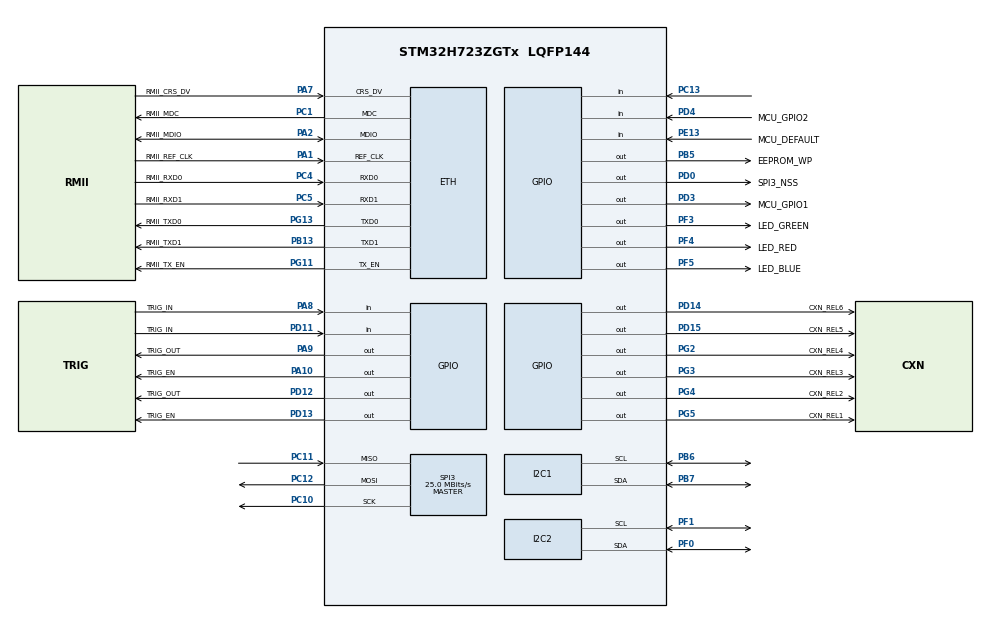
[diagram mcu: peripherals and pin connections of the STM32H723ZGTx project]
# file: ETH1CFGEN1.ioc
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CORTEX_M7.AccessPermission-Cortex_Memory_Protection_Unit_Region0_Settings=MPU_REGION_NO_ACCESS
CORTEX_M7.AccessPermission-Cortex_Memory_Protection_Unit_Region1_Settings=MPU_REGION_FULL_ACCESS
CORTEX_M7.AccessPermission-Cortex_Memory_Protection_Unit_Region2_Settings=MPU_REGION_FULL_ACCESS
CORTEX_M7.AccessPermission_S-Cortex_Memory_Protection_Unit_Region1_Settings_S=MPU_REGION_FULL_ACCESS
CORTEX_M7.AccessPermission_S-Cortex_Memory_Protection_Unit_Region2_Settings_S=MPU_REGION_FULL_ACCESS
CORTEX_M7.BaseAddress-Cortex_Memory_Protection_Unit_Region0_Settings=0x0
CORTEX_M7.BaseAddress-Cortex_Memory_Protection_Unit_Region1_Settings=0x30000000
CORTEX_M7.BaseAddress-Cortex_Memory_Protection_Unit_Region2_Settings=0x30004000
CORTEX_M7.BaseAddress_S-Cortex_Memory_Protection_Unit_Region1_Settings_S=0x30000000
CORTEX_M7.BaseAddress_S-Cortex_Memory_Protection_Unit_Region2_Settings_S=0x30000000
CORTEX_M7.CPU_DCache=Enabled
CORTEX_M7.CPU_ICache=Enabled
CORTEX_M7.DisableExec-Cortex_Memory_Protection_Unit_Region0_Settings=MPU_INSTRUCTION_ACCESS_DISABLE
CORTEX_M7.DisableExec-Cortex_Memory_Protection_Unit_Region1_Settings=MPU_INSTRUCTION_ACCESS_ENABLE
CORTEX_M7.DisableExec_S-Cortex_Memory_Protection_Unit_Region1_Settings_S=MPU_INSTRUCTION_ACCESS_DISABLE
CORTEX_M7.DisableExec_S-Cortex_Memory_Protection_Unit_Region2_Settings_S=MPU_INSTRUCTION_ACCESS_DISABLE
CORTEX_M7.Enable-Cortex_Memory_Protection_Unit_Region0_Settings=MPU_REGION_ENABLE
CORTEX_M7.Enable-Cortex_Memory_Protection_Unit_Region1_Settings=MPU_REGION_ENABLE
CORTEX_M7.Enable-Cortex_Memory_Protection_Unit_Region2_Settings=MPU_REGION_ENABLE
CORTEX_M7.Enable_S-Cortex_Memory_Protection_Unit_Region1_Settings_S=MPU_REGION_ENABLE
CORTEX_M7.Enable_S-Cortex_Memory_Protection_Unit_Region2_Settings_S=MPU_REGION_ENABLE
CORTEX_M7.IsBufferable-Cortex_Memory_Protection_Unit_Region0_Settings=MPU_ACCESS_BUFFERABLE
CORTEX_M7.IsBufferable-Cortex_Memory_Protection_Unit_Region1_Settings=MPU_ACCESS_BUFFERABLE
CORTEX_M7.IsBufferable_S-Cortex_Memory_Protection_Unit_Region2_Settings_S=MPU_ACCESS_BUFFERABLE
CORTEX_M7.IsShareable-Cortex_Memory_Protection_Unit_Region0_Settings=MPU_ACCESS_SHAREABLE
CORTEX_M7.IsShareable-Cortex_Memory_Protection_Unit_Region1_Settings=MPU_ACCESS_NOT_SHAREABLE
CORTEX_M7.IsShareable-Cortex_Memory_Protection_Unit_Region2_Settings=MPU_ACCESS_SHAREABLE
CORTEX_M7.IsShareable_S-Cortex_Memory_Protection_Unit_Region2_Settings_S=MPU_ACCESS_SHAREABLE
CORTEX_M7.MPU_Control=MPU_PRIVILEGED_DEFAULT
CORTEX_M7.Size-Cortex_Memory_Protection_Unit_Region0_Settings=MPU_REGION_SIZE_4GB
CORTEX_M7.Size-Cortex_Memory_Protection_Unit_Region1_Settings=MPU_REGION_SIZE_1KB
CORTEX_M7.Size-Cortex_Memory_Protection_Unit_Region2_Settings=MPU_REGION_SIZE_16KB
CORTEX_M7.Size_S-Cortex_Memory_Protection_Unit_Region1_Settings_S=MPU_REGION_SIZE_1KB
CORTEX_M7.Size_S-Cortex_Memory_Protection_Unit_Region2_Settings_S=MPU_REGION_SIZE_512B
CORTEX_M7.SubRegionDisable-Cortex_Memory_Protection_Unit_Region0_Settings=0x87
CORTEX_M7.TypeExtField-Cortex_Memory_Protection_Unit_Region0_Settings=MPU_TEX_LEVEL0
CORTEX_M7.TypeExtField-Cortex_Memory_Protection_Unit_Region2_Settings=MPU_TEX_LEVEL1
CORTEX_M7.TypeExtField_S-Cortex_Memory_Protection_Unit_Region1_Settings_S=MPU_TEX_LEVEL0
CORTEX_M7.default_mode_Activation=0
ETH.MediaInterface=HAL_ETH_RMII_MODE
FREERTOS.Tasks01=defaultTask,24,512,StartDefaultTask,Default,NULL,Dynamic,NULL,NULL
FREERTOS.configUSE_NEWLIB_REENTRANT=1
I2C1.Timing=0x20A0A3F6
I2C2.Timing=0x20A0A3F6
LWIP.BSP.number=1
LWIP.IP_ADDRESS=192.168.001.124
LWIP.LWIP_DHCP=0
LWIP.LWIP_RAM_HEAP_POINTER=0x30004000
LWIP.MEM_SIZE=1024*14
LWIP.NETMASK_ADDRESS=255.255.255.000
LWIP.TCP_MSS=1460
LWIP.TCP_SND_BUF=5840
LWIP.TCP_SND_QUEUELEN=16
LWIP.Version=v2.1.2_Cube
LWIP0.BSP.STBoard=false
LWIP0.BSP.api=BSP_COMPONENT_DRIVER
LWIP0.BSP.component=LAN8742
LWIP0.BSP.instance=LAN8742
LWIP0.BSP.name=Driver_PHY
LWIP0.BSP.semaphore=S_LAN8742
LWIP0.BSP.solution=LAN8742
Mcu.Family=STM32H7
Mcu.Name=STM32H723ZGTx
Mcu.Package=LQFP144
NVIC.ETH_IRQn=true\:5\:0\:false\:false\:true\:true\:true\:true\:true
NVIC.PriorityGroup=NVIC_PRIORITYGROUP_4
NVIC.TIM6_DAC_IRQn=true\:15\:0\:false\:false\:true\:false\:false\:true\:true
NVIC.TimeBase=TIM6_DAC_IRQn
NVIC.TimeBaseIP=TIM6
PA1.GPIO_Label=RMII_REF_CLK
PA1.GPIO_Speed=GPIO_SPEED_FREQ_VERY_HIGH
PA1.Mode=RMII
PA1.Signal=ETH_REF_CLK
PA10.GPIO_Label=TRIG_EN
PA10.Signal=GPIO_Output
PA13(JTMS/SWDIO).GPIO_Label=SWDIO
PA13(JTMS/SWDIO).Mode=Trace_Asynchronous_SW
PA13(JTMS/SWDIO).Signal=DEBUG_JTMS-SWDIO
PA14(JTCK/SWCLK).GPIO_Label=SWCLK
PA14(JTCK/SWCLK).Mode=Trace_Asynchronous_SW
PA14(JTCK/SWCLK).Signal=DEBUG_JTCK-SWCLK
PA2.GPIO_Label=RMII_MDIO
PA2.GPIO_Speed=GPIO_SPEED_FREQ_VERY_HIGH
PA2.Mode=RMII
PA2.Signal=ETH_MDIO
PA7.GPIO_Label=RMII_CRS_DV
PA7.GPIO_Speed=GPIO_SPEED_FREQ_VERY_HIGH
PA7.Mode=RMII
PA7.Signal=ETH_CRS_DV
PA8.GPIO_Label=TRIG_IN
PA8.Signal=GPIO_Input
PA9.GPIO_Label=TRIG_OUT
PA9.Signal=GPIO_Output
PB13.GPIO_Label=RMII_TXD1
PB13.GPIO_Speed=GPIO_SPEED_FREQ_VERY_HIGH
PB13.Mode=RMII
PB13.Signal=ETH_TXD1
PB3(JTDO/TRACESWO).GPIO_Label=SWO
PB3(JTDO/TRACESWO).Mode=Trace_Asynchronous_SW
PB3(JTDO/TRACESWO).Signal=DEBUG_JTDO-SWO
PB5.GPIO_Label=EEPROM_WP
PB5.Signal=GPIO_Output
PB6.Mode=I2C
PB6.Signal=I2C1_SCL
PB7.Mode=I2C
PB7.Signal=I2C1_SDA
PC1.GPIO_Label=RMII_MDC
PC1.Mode=RMII
PC1.Signal=ETH_MDC
PC10.Mode=Full_Duplex_Master
PC10.Signal=SPI3_SCK
PC11.Mode=Full_Duplex_Master
PC11.Signal=SPI3_MISO
PC12.Mode=Full_Duplex_Master
PC12.Signal=SPI3_MOSI
PC13.Signal=GPIO_Input
PC4.GPIO_Label=RMII_RXD0
PC4.GPIO_Speed=GPIO_SPEED_FREQ_VERY_HIGH
PC4.Mode=RMII
PC4.Signal=ETH_RXD0
PC5.GPIO_Label=RMII_RXD1
PC5.GPIO_Speed=GPIO_SPEED_FREQ_VERY_HIGH
PC5.Mode=RMII
PC5.Signal=ETH_RXD1
PD0.GPIO_Label=SPI3_NSS
PD0.GPIO_PuPd=GPIO_PULLDOWN
PD0.GPIO_Speed=GPIO_SPEED_FREQ_VERY_HIGH
PD0.PinState=GPIO_PIN_SET
PD0.Signal=GPIO_Output
PD11.GPIO_Label=TRIG_IN
PD11.Signal=GPIO_Input
PD12.GPIO_Label=TRIG_OUT
PD12.Signal=GPIO_Output
PD13.GPIO_Label=TRIG_EN
PD13.Signal=GPIO_Output
PD14.GPIO_Label=CXN_REL6
PD14.Signal=GPIO_Output
PD15.GPIO_Label=CXN_REL5
PD15.Signal=GPIO_Output
PD3.GPIO_Label=MCU_GPIO1
PD3.GPIO_Speed=GPIO_SPEED_FREQ_HIGH
PD3.PinState=GPIO_PIN_SET
PD3.Signal=GPIO_Output
PD4.GPIO_Label=MCU_GPIO2
PD4.Signal=GPIO_Input
PE13.GPIO_Label=MCU_DEFAULT
PE13.Signal=GPIO_Input
PF0.Mode=I2C
PF0.Signal=I2C2_SDA
PF1.Mode=I2C
PF1.Signal=I2C2_SCL
PF3.GPIO_Label=LED_GREEN
PF3.Signal=GPIO_Output
PF4.GPIO_Label=LED_RED
PF4.Signal=GPIO_Output
PF5.GPIO_Label=LED_BLUE
PF5.Signal=GPIO_Output
PG11.GPIO_Label=RMII_TX_EN
PG11.GPIO_Speed=GPIO_SPEED_FREQ_VERY_HIGH
PG11.Mode=RMII
PG11.Signal=ETH_TX_EN
PG13.GPIO_Label=RMII_TXD0
PG13.GPIO_Speed=GPIO_SPEED_FREQ_VERY_HIGH
PG13.Mode=RMII
PG13.Signal=ETH_TXD0
PG2.GPIO_Label=CXN_REL4
PG2.Signal=GPIO_Output
PG3.GPIO_Label=CXN_REL3
PG3.Signal=GPIO_Output
PG4.GPIO_Label=CXN_REL2
PG4.Signal=GPIO_Output
PG5.GPIO_Label=CXN_REL1
PG5.Signal=GPIO_Output
PH0-OSC_IN.GPIO_Label=MCO
PH0-OSC_IN.Mode=HSE-External-Clock-Source
PH0-OSC_IN.Signal=RCC_OSC_IN
ProjectManager.HeapSize=0x200
ProjectManager.StackSize=0x400
ProjectManager.TargetToolchain=STM32CubeIDE
RCC.ADCFreq_Value=76000000
RCC.APB1Freq_Value=125000000
RCC.APB2Freq_Value=125000000
RCC.APB3Freq_Value=125000000
RCC.APB4Freq_Value=125000000
RCC.CortexFreq_Value=500000000
RCC.D1PPRE=RCC_APB3_DIV2
RCC.D2PPRE1=RCC_APB1_DIV2
RCC.D2PPRE2=RCC_APB2_DIV2
RCC.D3PPRE=RCC_APB4_DIV2
RCC.DIVM1=4
RCC.DIVM2=1
RCC.DIVN1=250
RCC.DIVN2=19
RCC.DIVP1=1
RCC.DIVQ1=5
RCC.HCLKFreq_Value=250000000
RCC.HPRE=RCC_HCLK_DIV2
RCC.HSE_VALUE=8000000
RCC.PLLFRACN=0
RCC.PLLSourceVirtual=RCC_PLLSOURCE_HSE
RCC.SYSCLKFreq_VALUE=500000000
RCC.SYSCLKSource=RCC_SYSCLKSOURCE_PLLCLK
RCC.USBCLockSelection=RCC_USBCLKSOURCE_HSI48
RCC.USBFreq_Value=48000000
SPI3.BaudRatePrescaler=SPI_BAUDRATEPRESCALER_4
SPI3.CLKPhase=SPI_PHASE_1EDGE
SPI3.CLKPolarity=SPI_POLARITY_LOW
SPI3.CalculateBaudRate=25.0 MBits/s
SPI3.DataSize=SPI_DATASIZE_8BIT
SPI3.Direction=SPI_DIRECTION_2LINES
SPI3.FirstBit=SPI_FIRSTBIT_MSB
SPI3.Mode=SPI_MODE_MASTER
SPI3.NSSPMode=SPI_NSS_PULSE_ENABLE
SPI3.VirtualType=VM_MASTER
TIM3.Period=0xFFFF-1
TIM3.Prescaler=216 -1
VP_FREERTOS_VS_CMSIS_V2.Mode=CMSIS_V2
VP_LWIP_VS_Enabled.Mode=Enabled
VP_SYS_VS_tim6.Mode=TIM6
VP_TIM3_VS_ClockSourceINT.Mode=Internal
board=NUCLEO-H723ZG

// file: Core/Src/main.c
/* USER CODE BEGIN Header */
/**
  ******************************************************************************
  * @file           : main.c
  * @brief          : Main program body
  ******************************************************************************
  * @attention
  *
  * Copyright (c) 2023 STMicroelectronics.
  * All rights reserved.
  *
  * This software is licensed under terms that can be found in the LICENSE file
  * in the root directory of this software component.
  * If no LICENSE file comes with this software, it is provided AS-IS.
  *
  ******************************************************************************
  */
/* USER CODE END Header */
#include "main.h"
#include "cmsis_os.h"
#include "lwip.h"

/* USER CODE BEGIN Includes */
#include "scpi_server.h"
#include "BSP.h"
/* USER CODE END Includes */

I2C_HandleTypeDef hi2c1;
I2C_HandleTypeDef hi2c2;

SPI_HandleTypeDef hspi3;

TIM_HandleTypeDef htim3;

/* Definitions for defaultTask */
osThreadId_t defaultTaskHandle;
const osThreadAttr_t defaultTask_attributes = {
  .name = "defaultTask",
  .stack_size = 512 * 4,
  .priority = (osPriority_t) osPriorityNormal,
};
/* USER CODE BEGIN PV */

uint32_t PSSI_HAL_PSSI_TransmitComplete_count = 0;
uint32_t PSSI_HAL_PSSI_ReceiveComplete_count = 0;
uint32_t PSSI_HAL_PSSI_ErrorCallback_count = 0;

/* USER CODE END PV */

void SystemClock_Config(void);
static void MPU_Config(void);
static void MX_GPIO_Init(void);
static void MX_TIM3_Init(void);
static void MX_I2C1_Init(void);
static void MX_I2C2_Init(void);
static void MX_SPI3_Init(void);
void StartDefaultTask(void *argument);

/* USER CODE BEGIN 0 */

extern bsp_t bsp;

/*
void HAL_PSSI_RxCpltCallback(PSSI_HandleTypeDef *hpssi)
{
  PSSI_HAL_PSSI_ReceiveComplete_count++;
}

void HAL_PSSI_TxCpltCallback(PSSI_HandleTypeDef *hpssi)
{
  PSSI_HAL_PSSI_TransmitComplete_count++;
}

void HAL_PSSI_ErrorCallback(PSSI_HandleTypeDef *hpssi)
{
  PSSI_HAL_PSSI_ErrorCallback_count++;
}
*/
/* USER CODE END 0 */

int main(void)
{

  /* MPU Configuration--------------------------------------------------------*/
  MPU_Config();
/* Enable the CPU Cache */

  /* Enable I-Cache---------------------------------------------------------*/
  SCB_EnableICache();

  /* Enable D-Cache---------------------------------------------------------*/
  SCB_EnableDCache();

  /* MCU Configuration--------------------------------------------------------*/

  /* Reset of all peripherals, Initializes the Flash interface and the Systick. */
  HAL_Init();

  /* Configure the system clock */
  SystemClock_Config();

  /* Initialize all configured peripherals */
  MX_GPIO_Init();
  MX_TIM3_Init();
  MX_I2C1_Init();
  MX_I2C2_Init();
  MX_SPI3_Init();

  /* Init scheduler */
  osKernelInitialize();

  /* Create the thread(s) */
  /* creation of defaultTask */
  defaultTaskHandle = osThreadNew(StartDefaultTask, NULL, &defaultTask_attributes);

  /* Start scheduler */
  osKernelStart();

  /* We should never get here as control is now taken by the scheduler */
  /* Infinite loop */
  while (1)
  {

  }
}

void SystemClock_Config(void)
{
  RCC_OscInitTypeDef RCC_OscInitStruct = {0};
  RCC_ClkInitTypeDef RCC_ClkInitStruct = {0};

  /** Supply configuration update enable
  */
  HAL_PWREx_ConfigSupply(PWR_LDO_SUPPLY);

  /** Configure the main internal regulator output voltage
  */
  __HAL_PWR_VOLTAGESCALING_CONFIG(PWR_REGULATOR_VOLTAGE_SCALE0);

  while(!__HAL_PWR_GET_FLAG(PWR_FLAG_VOSRDY)) {}

  /** Initializes the RCC Oscillators according to the specified parameters
  * in the RCC_OscInitTypeDef structure.
  */
  RCC_OscInitStruct.OscillatorType = RCC_OSCILLATORTYPE_HSE;
  RCC_OscInitStruct.HSEState = RCC_HSE_BYPASS;
  RCC_OscInitStruct.PLL.PLLState = RCC_PLL_ON;
  RCC_OscInitStruct.PLL.PLLSource = RCC_PLLSOURCE_HSE;
  RCC_OscInitStruct.PLL.PLLM = 4;
  RCC_OscInitStruct.PLL.PLLN = 250;
  RCC_OscInitStruct.PLL.PLLP = 1;
  RCC_OscInitStruct.PLL.PLLQ = 5;
  RCC_OscInitStruct.PLL.PLLR = 2;
  RCC_OscInitStruct.PLL.PLLRGE = RCC_PLL1VCIRANGE_1;
  RCC_OscInitStruct.PLL.PLLVCOSEL = RCC_PLL1VCOWIDE;
  RCC_OscInitStruct.PLL.PLLFRACN = 0;
  if (HAL_RCC_OscConfig(&RCC_OscInitStruct) != HAL_OK)
  {
    Error_Handler();
  }

  /** Initializes the CPU, AHB and APB buses clocks
  */
  RCC_ClkInitStruct.ClockType = RCC_CLOCKTYPE_HCLK|RCC_CLOCKTYPE_SYSCLK
                              |RCC_CLOCKTYPE_PCLK1|RCC_CLOCKTYPE_PCLK2
                              |RCC_CLOCKTYPE_D3PCLK1|RCC_CLOCKTYPE_D1PCLK1;
  RCC_ClkInitStruct.SYSCLKSource = RCC_SYSCLKSOURCE_PLLCLK;
  RCC_ClkInitStruct.SYSCLKDivider = RCC_SYSCLK_DIV1;
  RCC_ClkInitStruct.AHBCLKDivider = RCC_HCLK_DIV2;
  RCC_ClkInitStruct.APB3CLKDivider = RCC_APB3_DIV2;
  RCC_ClkInitStruct.APB1CLKDivider = RCC_APB1_DIV2;
  RCC_ClkInitStruct.APB2CLKDivider = RCC_APB2_DIV2;
  RCC_ClkInitStruct.APB4CLKDivider = RCC_APB4_DIV2;

  if (HAL_RCC_ClockConfig(&RCC_ClkInitStruct, FLASH_LATENCY_3) != HAL_OK)
  {
    Error_Handler();
  }
}

static void MX_I2C1_Init(void)
{

  hi2c1.Instance = I2C1;
  hi2c1.Init.Timing = 0x20A0A3F6;
  hi2c1.Init.OwnAddress1 = 0;
  hi2c1.Init.AddressingMode = I2C_ADDRESSINGMODE_7BIT;
  hi2c1.Init.DualAddressMode = I2C_DUALADDRESS_DISABLE;
  hi2c1.Init.OwnAddress2 = 0;
  hi2c1.Init.OwnAddress2Masks = I2C_OA2_NOMASK;
  hi2c1.Init.GeneralCallMode = I2C_GENERALCALL_DISABLE;
  hi2c1.Init.NoStretchMode = I2C_NOSTRETCH_DISABLE;
  if (HAL_I2C_Init(&hi2c1) != HAL_OK)
  {
    Error_Handler();
  }

  /** Configure Analogue filter
  */
  if (HAL_I2CEx_ConfigAnalogFilter(&hi2c1, I2C_ANALOGFILTER_ENABLE) != HAL_OK)
  {
    Error_Handler();
  }

  /** Configure Digital filter
  */
  if (HAL_I2CEx_ConfigDigitalFilter(&hi2c1, 0) != HAL_OK)
  {
    Error_Handler();
  }

}

static void MX_I2C2_Init(void)
{

  hi2c2.Instance = I2C2;
  hi2c2.Init.Timing = 0x20A0A3F6;
  hi2c2.Init.OwnAddress1 = 0;
  hi2c2.Init.AddressingMode = I2C_ADDRESSINGMODE_7BIT;
  hi2c2.Init.DualAddressMode = I2C_DUALADDRESS_DISABLE;
  hi2c2.Init.OwnAddress2 = 0;
  hi2c2.Init.OwnAddress2Masks = I2C_OA2_NOMASK;
  hi2c2.Init.GeneralCallMode = I2C_GENERALCALL_DISABLE;
  hi2c2.Init.NoStretchMode = I2C_NOSTRETCH_DISABLE;
  if (HAL_I2C_Init(&hi2c2) != HAL_OK)
  {
    Error_Handler();
  }

  /** Configure Analogue filter
  */
  if (HAL_I2CEx_ConfigAnalogFilter(&hi2c2, I2C_ANALOGFILTER_ENABLE) != HAL_OK)
  {
    Error_Handler();
  }

  /** Configure Digital filter
  */
  if (HAL_I2CEx_ConfigDigitalFilter(&hi2c2, 0) != HAL_OK)
  {
    Error_Handler();
  }

}

static void MX_SPI3_Init(void)
{

  /* SPI3 parameter configuration*/
  hspi3.Instance = SPI3;
  hspi3.Init.Mode = SPI_MODE_MASTER;
  hspi3.Init.Direction = SPI_DIRECTION_2LINES;
  hspi3.Init.DataSize = SPI_DATASIZE_8BIT;
  hspi3.Init.CLKPolarity = SPI_POLARITY_LOW;
  hspi3.Init.CLKPhase = SPI_PHASE_1EDGE;
  hspi3.Init.NSS = SPI_NSS_SOFT;
  hspi3.Init.BaudRatePrescaler = SPI_BAUDRATEPRESCALER_4;
  hspi3.Init.FirstBit = SPI_FIRSTBIT_MSB;
  hspi3.Init.TIMode = SPI_TIMODE_DISABLE;
  hspi3.Init.CRCCalculation = SPI_CRCCALCULATION_DISABLE;
  hspi3.Init.CRCPolynomial = 0x0;
  hspi3.Init.NSSPMode = SPI_NSS_PULSE_ENABLE;
  hspi3.Init.NSSPolarity = SPI_NSS_POLARITY_LOW;
  hspi3.Init.FifoThreshold = SPI_FIFO_THRESHOLD_01DATA;
  hspi3.Init.TxCRCInitializationPattern = SPI_CRC_INITIALIZATION_ALL_ZERO_PATTERN;
  hspi3.Init.RxCRCInitializationPattern = SPI_CRC_INITIALIZATION_ALL_ZERO_PATTERN;
  hspi3.Init.MasterSSIdleness = SPI_MASTER_SS_IDLENESS_00CYCLE;
  hspi3.Init.MasterInterDataIdleness = SPI_MASTER_INTERDATA_IDLENESS_00CYCLE;
  hspi3.Init.MasterReceiverAutoSusp = SPI_MASTER_RX_AUTOSUSP_DISABLE;
  hspi3.Init.MasterKeepIOState = SPI_MASTER_KEEP_IO_STATE_DISABLE;
  hspi3.Init.IOSwap = SPI_IO_SWAP_DISABLE;
  if (HAL_SPI_Init(&hspi3) != HAL_OK)
  {
    Error_Handler();
  }

}

static void MX_TIM3_Init(void)
{

  TIM_ClockConfigTypeDef sClockSourceConfig = {0};
  TIM_MasterConfigTypeDef sMasterConfig = {0};

  htim3.Instance = TIM3;
  htim3.Init.Prescaler = 216 -1;
  htim3.Init.CounterMode = TIM_COUNTERMODE_UP;
  htim3.Init.Period = 0xFFFF-1;
  htim3.Init.ClockDivision = TIM_CLOCKDIVISION_DIV1;
  htim3.Init.AutoReloadPreload = TIM_AUTORELOAD_PRELOAD_DISABLE;
  if (HAL_TIM_Base_Init(&htim3) != HAL_OK)
  {
    Error_Handler();
  }
  sClockSourceConfig.ClockSource = TIM_CLOCKSOURCE_INTERNAL;
  if (HAL_TIM_ConfigClockSource(&htim3, &sClockSourceConfig) != HAL_OK)
  {
    Error_Handler();
  }
  sMasterConfig.MasterOutputTrigger = TIM_TRGO_RESET;
  sMasterConfig.MasterSlaveMode = TIM_MASTERSLAVEMODE_DISABLE;
  if (HAL_TIMEx_MasterConfigSynchronization(&htim3, &sMasterConfig) != HAL_OK)
  {
    Error_Handler();
  }

}

static void MX_GPIO_Init(void)
{
  GPIO_InitTypeDef GPIO_InitStruct = {0};

  /* GPIO Ports Clock Enable */
  __HAL_RCC_GPIOC_CLK_ENABLE();
  __HAL_RCC_GPIOF_CLK_ENABLE();
  __HAL_RCC_GPIOH_CLK_ENABLE();
  __HAL_RCC_GPIOA_CLK_ENABLE();
  __HAL_RCC_GPIOE_CLK_ENABLE();
  __HAL_RCC_GPIOB_CLK_ENABLE();
  __HAL_RCC_GPIOD_CLK_ENABLE();
  __HAL_RCC_GPIOG_CLK_ENABLE();

  /*Configure GPIO pin Output Level */
  HAL_GPIO_WritePin(GPIOF, LED_GREEN_Pin|LED_RED_Pin|LED_BLUE_Pin, GPIO_PIN_RESET);

  /*Configure GPIO pin Output Level */
  HAL_GPIO_WritePin(GPIOD, TRIG_OUT_Pin|TRIG_EN_Pin|CXN_REL6_Pin|CXN_REL5_Pin, GPIO_PIN_RESET);

  /*Configure GPIO pin Output Level */
  HAL_GPIO_WritePin(GPIOG, CXN_REL4_Pin|CXN_REL3_Pin|CXN_REL2_Pin|CXN_REL1_Pin, GPIO_PIN_RESET);

  /*Configure GPIO pin Output Level */
  HAL_GPIO_WritePin(GPIOA, TRIG_OUTA9_Pin|TRIG_ENA10_Pin, GPIO_PIN_RESET);

  /*Configure GPIO pin Output Level */
  HAL_GPIO_WritePin(GPIOD, SPI3_NSS_Pin|MCU_GPIO1_Pin, GPIO_PIN_SET);

  /*Configure GPIO pin Output Level */
  HAL_GPIO_WritePin(EEPROM_WP_GPIO_Port, EEPROM_WP_Pin, GPIO_PIN_RESET);

  /*Configure GPIO pin : PC13 */
  GPIO_InitStruct.Pin = GPIO_PIN_13;
  GPIO_InitStruct.Mode = GPIO_MODE_INPUT;
  GPIO_InitStruct.Pull = GPIO_NOPULL;
  HAL_GPIO_Init(GPIOC, &GPIO_InitStruct);

  /*Configure GPIO pins : LED_GREEN_Pin LED_RED_Pin LED_BLUE_Pin */
  GPIO_InitStruct.Pin = LED_GREEN_Pin|LED_RED_Pin|LED_BLUE_Pin;
  GPIO_InitStruct.Mode = GPIO_MODE_OUTPUT_PP;
  GPIO_InitStruct.Pull = GPIO_NOPULL;
  GPIO_InitStruct.Speed = GPIO_SPEED_FREQ_LOW;
  HAL_GPIO_Init(GPIOF, &GPIO_InitStruct);

  /*Configure GPIO pin : MCU_DEFAULT_Pin */
  GPIO_InitStruct.Pin = MCU_DEFAULT_Pin;
  GPIO_InitStruct.Mode = GPIO_MODE_INPUT;
  GPIO_InitStruct.Pull = GPIO_NOPULL;
  HAL_GPIO_Init(MCU_DEFAULT_GPIO_Port, &GPIO_InitStruct);

  /*Configure GPIO pins : TRIG_IN_Pin MCU_GPIO2_Pin */
  GPIO_InitStruct.Pin = TRIG_IN_Pin|MCU_GPIO2_Pin;
  GPIO_InitStruct.Mode = GPIO_MODE_INPUT;
  GPIO_InitStruct.Pull = GPIO_NOPULL;
  HAL_GPIO_Init(GPIOD, &GPIO_InitStruct);

  /*Configure GPIO pins : TRIG_OUT_Pin TRIG_EN_Pin CXN_REL6_Pin CXN_REL5_Pin */
  GPIO_InitStruct.Pin = TRIG_OUT_Pin|TRIG_EN_Pin|CXN_REL6_Pin|CXN_REL5_Pin;
  GPIO_InitStruct.Mode = GPIO_MODE_OUTPUT_PP;
  GPIO_InitStruct.Pull = GPIO_NOPULL;
  GPIO_InitStruct.Speed = GPIO_SPEED_FREQ_LOW;
  HAL_GPIO_Init(GPIOD, &GPIO_InitStruct);

  /*Configure GPIO pins : CXN_REL4_Pin CXN_REL3_Pin CXN_REL2_Pin CXN_REL1_Pin */
  GPIO_InitStruct.Pin = CXN_REL4_Pin|CXN_REL3_Pin|CXN_REL2_Pin|CXN_REL1_Pin;
  GPIO_InitStruct.Mode = GPIO_MODE_OUTPUT_PP;
  GPIO_InitStruct.Pull = GPIO_NOPULL;
  GPIO_InitStruct.Speed = GPIO_SPEED_FREQ_LOW;
  HAL_GPIO_Init(GPIOG, &GPIO_InitStruct);

  /*Configure GPIO pin : TRIG_INA8_Pin */
  GPIO_InitStruct.Pin = TRIG_INA8_Pin;
  GPIO_InitStruct.Mode = GPIO_MODE_INPUT;
  GPIO_InitStruct.Pull = GPIO_NOPULL;
  HAL_GPIO_Init(TRIG_INA8_GPIO_Port, &GPIO_InitStruct);

  /*Configure GPIO pins : TRIG_OUTA9_Pin TRIG_ENA10_Pin */
  GPIO_InitStruct.Pin = TRIG_OUTA9_Pin|TRIG_ENA10_Pin;
  GPIO_InitStruct.Mode = GPIO_MODE_OUTPUT_PP;
  GPIO_InitStruct.Pull = GPIO_NOPULL;
  GPIO_InitStruct.Speed = GPIO_SPEED_FREQ_LOW;
  HAL_GPIO_Init(GPIOA, &GPIO_InitStruct);

  /*Configure GPIO pin : SPI3_NSS_Pin */
  GPIO_InitStruct.Pin = SPI3_NSS_Pin;
  GPIO_InitStruct.Mode = GPIO_MODE_OUTPUT_PP;
  GPIO_InitStruct.Pull = GPIO_PULLDOWN;
  GPIO_InitStruct.Speed = GPIO_SPEED_FREQ_VERY_HIGH;
  HAL_GPIO_Init(SPI3_NSS_GPIO_Port, &GPIO_InitStruct);

  /*Configure GPIO pin : MCU_GPIO1_Pin */
  GPIO_InitStruct.Pin = MCU_GPIO1_Pin;
  GPIO_InitStruct.Mode = GPIO_MODE_OUTPUT_PP;
  GPIO_InitStruct.Pull = GPIO_NOPULL;
  GPIO_InitStruct.Speed = GPIO_SPEED_FREQ_HIGH;
  HAL_GPIO_Init(MCU_GPIO1_GPIO_Port, &GPIO_InitStruct);

  /*Configure GPIO pin : EEPROM_WP_Pin */
  GPIO_InitStruct.Pin = EEPROM_WP_Pin;
  GPIO_InitStruct.Mode = GPIO_MODE_OUTPUT_PP;
  GPIO_InitStruct.Pull = GPIO_NOPULL;
  GPIO_InitStruct.Speed = GPIO_SPEED_FREQ_LOW;
  HAL_GPIO_Init(EEPROM_WP_GPIO_Port, &GPIO_InitStruct);

}

void StartDefaultTask(void *argument)
{
  /* init code for LWIP */
  MX_LWIP_Init();
  /* USER CODE BEGIN 5 */
  osDelay(pdMS_TO_TICKS(100));
  SCPI_ServerInit();
  /* Infinite loop */
  for(;;)
  {
    osDelay(500);
    HAL_GPIO_TogglePin(LED_GREEN_GPIO_Port, LED_GREEN_Pin);
  }
  /* USER CODE END 5 */
}

/* MPU Configuration */

void MPU_Config(void)
{
  MPU_Region_InitTypeDef MPU_InitStruct = {0};

  /* Disables the MPU */
  HAL_MPU_Disable();

  /** Initializes and configures the Region and the memory to be protected
  */
  MPU_InitStruct.Enable = MPU_REGION_ENABLE;
  MPU_InitStruct.Number = MPU_REGION_NUMBER0;
  MPU_InitStruct.BaseAddress = 0x0;
  MPU_InitStruct.Size = MPU_REGION_SIZE_4GB;
  MPU_InitStruct.SubRegionDisable = 0x87;
  MPU_InitStruct.TypeExtField = MPU_TEX_LEVEL0;
  MPU_InitStruct.AccessPermission = MPU_REGION_NO_ACCESS;
  MPU_InitStruct.DisableExec = MPU_INSTRUCTION_ACCESS_DISABLE;
  MPU_InitStruct.IsShareable = MPU_ACCESS_SHAREABLE;
  MPU_InitStruct.IsCacheable = MPU_ACCESS_NOT_CACHEABLE;
  MPU_InitStruct.IsBufferable = MPU_ACCESS_BUFFERABLE;

  HAL_MPU_ConfigRegion(&MPU_InitStruct);

  /** Initializes and configures the Region and the memory to be protected
  */
  MPU_InitStruct.Number = MPU_REGION_NUMBER1;
  MPU_InitStruct.BaseAddress = 0x30000000;
  MPU_InitStruct.Size = MPU_REGION_SIZE_1KB;
  MPU_InitStruct.SubRegionDisable = 0x0;
  MPU_InitStruct.AccessPermission = MPU_REGION_FULL_ACCESS;
  MPU_InitStruct.DisableExec = MPU_INSTRUCTION_ACCESS_ENABLE;
  MPU_InitStruct.IsShareable = MPU_ACCESS_NOT_SHAREABLE;

  HAL_MPU_ConfigRegion(&MPU_InitStruct);

  /** Initializes and configures the Region and the memory to be protected
  */
  MPU_InitStruct.Number = MPU_REGION_NUMBER2;
  MPU_InitStruct.BaseAddress = 0x30004000;
  MPU_InitStruct.Size = MPU_REGION_SIZE_16KB;
  MPU_InitStruct.TypeExtField = MPU_TEX_LEVEL1;
  MPU_InitStruct.IsShareable = MPU_ACCESS_SHAREABLE;
  MPU_InitStruct.IsBufferable = MPU_ACCESS_NOT_BUFFERABLE;

  HAL_MPU_ConfigRegion(&MPU_InitStruct);
  /* Enables the MPU */
  HAL_MPU_Enable(MPU_PRIVILEGED_DEFAULT);

}

void HAL_TIM_PeriodElapsedCallback(TIM_HandleTypeDef *htim)
{
  if (htim->Instance == TIM6) {
    HAL_IncTick();
  }
}

void Error_Handler(void)
{
  /* USER CODE BEGIN Error_Handler_Debug */
	HAL_GPIO_WritePin(LED_RED_GPIO_Port, LED_RED_Pin, GPIO_PIN_SET);
  /* User can add his own implementation to report the HAL error return state */
  __disable_irq();
  while (1)
  {
  }
  /* USER CODE END Error_Handler_Debug */
}
